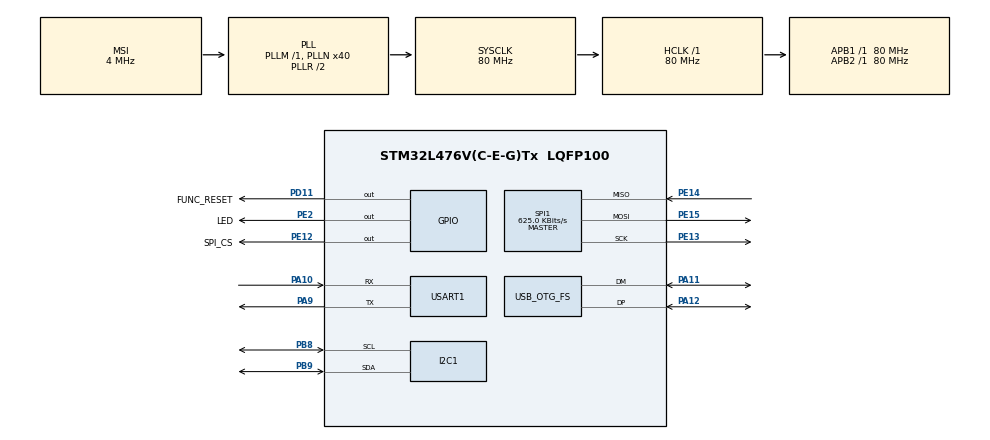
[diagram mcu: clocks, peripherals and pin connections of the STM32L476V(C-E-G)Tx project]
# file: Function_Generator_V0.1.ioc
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I2C1.Timing=0x10D19CE4
Mcu.Family=STM32L4
Mcu.Name=STM32L476V(C-E-G)Tx
Mcu.Package=LQFP100
NVIC.OTG_FS_IRQn=true\:0\:0\:false\:false\:true\:false\:true\:true
NVIC.PriorityGroup=NVIC_PRIORITYGROUP_4
PA10.Mode=Asynchronous
PA10.Signal=USART1_RX
PA11.Mode=Device_Only
PA11.Signal=USB_OTG_FS_DM
PA12.Mode=Device_Only
PA12.Signal=USB_OTG_FS_DP
PA13\ (JTMS-SWDIO).Mode=Serial_Wire
PA13\ (JTMS-SWDIO).Signal=SYS_JTMS-SWDIO
PA14\ (JTCK-SWCLK).Mode=Serial_Wire
PA14\ (JTCK-SWCLK).Signal=SYS_JTCK-SWCLK
PA9.Mode=Asynchronous
PA9.Signal=USART1_TX
PB8.Mode=I2C
PB8.Signal=I2C1_SCL
PB9.Mode=I2C
PB9.Signal=I2C1_SDA
PC14-OSC32_IN\ (PC14).Signal=RCC_OSC32_IN
PC15-OSC32_OUT\ (PC15).Signal=RCC_OSC32_OUT
PD11.GPIO_Label=FUNC_RESET
PD11.Signal=GPIO_Output
PE12.GPIO_Label=SPI_CS
PE12.Signal=GPIO_Output
PE13.Mode=Full_Duplex_Master
PE13.Signal=SPI1_SCK
PE14.Mode=Full_Duplex_Master
PE14.Signal=SPI1_MISO
PE15.Mode=Full_Duplex_Master
PE15.Signal=SPI1_MOSI
PE2.GPIO_Label=LED
PE2.Signal=GPIO_Output
ProjectManager.HeapSize=0x200
ProjectManager.StackSize=0x400
ProjectManager.TargetToolchain=CMake
RCC.ADCFreq_Value=48000000
RCC.AHBFreq_Value=80000000
RCC.APB1Freq_Value=80000000
RCC.APB1TimFreq_Value=80000000
RCC.APB2Freq_Value=80000000
RCC.APB2TimFreq_Value=80000000
RCC.CortexFreq_Value=80000000
RCC.HCLKFreq_Value=80000000
RCC.HSE_VALUE=8000000
RCC.HSI_VALUE=16000000
RCC.MSI_VALUE=4000000
RCC.PLLN=40
RCC.PLLSAI1N=24
RCC.SYSCLKFreq_VALUE=80000000
RCC.SYSCLKSource=RCC_SYSCLKSOURCE_PLLCLK
RCC.USBFreq_Value=48000000
RCC.VCOOutputFreq_Value=160000000
SPI1.BaudRatePrescaler=SPI_BAUDRATEPRESCALER_128
SPI1.CalculateBaudRate=625.0 KBits/s
SPI1.DataSize=SPI_DATASIZE_8BIT
SPI1.Direction=SPI_DIRECTION_2LINES
SPI1.Mode=SPI_MODE_MASTER
SPI1.VirtualType=VM_MASTER
USART1.VirtualMode-Asynchronous=VM_ASYNC
USB_DEVICE.CLASS_NAME_FS=CDC
USB_DEVICE.VirtualMode=Cdc
USB_DEVICE.VirtualModeFS=Cdc_FS
USB_OTG_FS.VirtualMode=Device_Only
VP_USB_DEVICE_VS_USB_DEVICE_CDC_FS.Mode=CDC_FS
board=custom

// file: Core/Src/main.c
/* USER CODE BEGIN Header */
/**
 ******************************************************************************
 * @file           : main.c
 * @brief          : Main program body
 ******************************************************************************
 * @attention
 *
 * Copyright (c) 2025 STMicroelectronics.
 * All rights reserved.
 *
 * This software is licensed under terms that can be found in the LICENSE file
 * in the root directory of this software component.
 * If no LICENSE file comes with this software, it is provided AS-IS.
 *
 ******************************************************************************
 */
/* USER CODE END Header */
#include "main.h"
#include "i2c.h"
#include "spi.h"
#include "usart.h"
#include "usb_device.h"
#include "gpio.h"
#include "usbd_cdc_if.h"
#include "ad9106.h"
#include "cli.h"

void SystemClock_Config(void);

int main(void)
{

  /* MCU Configuration--------------------------------------------------------*/

  /* Reset of all peripherals, Initializes the Flash interface and the Systick. */
  HAL_Init();

  /* Configure the system clock */
  SystemClock_Config();

  /* Initialize all configured peripherals */
  MX_GPIO_Init();
  MX_SPI1_Init();
  MX_USART1_UART_Init();
  MX_USB_DEVICE_Init();
  MX_I2C1_Init();
  /* USER CODE BEGIN 2 */

  HAL_Delay(200);

  HAL_GPIO_WritePin(SPI_CS_GPIO_Port, SPI_CS_Pin, GPIO_PIN_SET);
  HAL_GPIO_WritePin(LED_GPIO_Port, LED_Pin, GPIO_PIN_SET);

  AD9106_Init();
  AD9106_Reset();
  CLI_Init();

  // 2. Configure registers
  /*
    // (a) Power configuration: disable DAC1, DAC2, DAC4 (sleep), keep DAC3 active
    AD9106_WriteReg(0x01, 0b0000000000001101); // DAC1_SLEEP, DAC2_SLEEP, DAC4_SLEEP = 1

    HAL_Delay(10);

    AD9106_ReadReg(0x01);

    HAL_Delay(10);
    // (b) DDS tuning word (sets output frequency)
    AD9106_WriteReg(0x3E, 0x0000); // DDS_TW32 (MSB)

    HAL_Delay(10);
    AD9106_WriteReg(0x3F, 0xFF00); // DDS_TW1  (LSB) → Tuning word = 0x00A300

    HAL_Delay(10);

    AD9106_ReadReg(0x3F);
    HAL_Delay(10);
    // (c) Select waveform source for DAC3 = DDS
    AD9106_WriteReg(0x26, 0x0300); // PRESTORE_SEL3 = 3 (DDS), WAVE_SEL3 = 0 (prestored waveform)
    HAL_Delay(10);
    // (d) Set unity digital gain for DAC3
    AD9106_WriteReg(0x33, 0x0400); // DAC3_DGAIN = +1.0
    HAL_Delay(10);
    // (f) Enable pattern generator
    AD9106_WriteReg(0x1E, 0x0001); // RUN = 1
    HAL_Delay(10);
    AD9106_ReadReg(0x1E);
    HAL_Delay(10);
    // (e) Update all configuration shadow registers
    AD9106_WriteReg(0x1D, 0x0001); // RAMUPDATE = 1
    HAL_Delay(10);

  uint16_t AD910x_SPI_Register_Addresses[66] = {0x0000, 0x0001, 0x0002, 0x0003, 0x0004, 0x0005, 0x0006, 0x0007, 0x0008, 0x0009, 0x000a, 0x000b, 0x000c, 0x000d, 0x000e, 0x001f, 0x0020, 0x0022, 0x0023, 0x0024, 0x0025, 0x0026, 0x0027, 0x0028, 0x0029, 0x002a, 0x002b, 0x002c, 0x002d, 0x002e, 0x002f, 0x0030, 0x0031, 0x0032, 0x0033, 0x0034, 0x0035, 0x0036, 0x0037, 0x003e, 0x003f, 0x0040, 0x0041, 0x0042, 0x0043, 0x0044, 0x0045, 0x0047, 0x0050, 0x0051, 0x0052, 0x0053, 0x0054, 0x0055, 0x0056, 0x0057, 0x0058, 0x0059, 0x005a, 0x005b, 0x005c, 0x005d, 0x005e, 0x005f, 0x001e, 0x001d};
  uint16_t AD9106_example3_regval[66] = {0x0000, 0x0e00, 0x0000, 0x0000, 0x4000, 0x4000, 0x4000, 0x4000, 0x0000, 0x1f00, 0x1f00, 0x1f00, 0x1f00, 0x0000, 0x0000, 0x0000, 0x000e, 0x0000, 0x0000, 0x0000, 0x0000, 0x3232, 0x3232, 0x0111, 0xffff, 0x0101, 0x0101, 0x0003, 0x0000, 0x0000, 0x0000, 0x0000, 0x0000, 0x4000, 0x2000, 0x2000, 0x4000, 0x0001, 0x0200, 0x0a3d, 0x7100, 0x0000, 0x0000, 0x0000, 0x0000, 0x0000, 0x0000, 0x0000, 0x07d0, 0x0000, 0x0000, 0x0100, 0x03e8, 0x0000, 0x0000, 0x0100, 0x0bb8, 0x0000, 0x0000, 0x0100, 0x0fa0, 0x0000, 0x0000, 0x0100, 0x0001, 0x0001};
  uint16_t AD9106_example4_regval[66] = {0x0000, 0x0e00, 0x0000, 0x0000, 0x4000, 0x4000, 0x4000, 0x4000, 0x0000, 0x1f00, 0x1f00, 0x1f00, 0x1f00, 0x0000, 0x0000, 0x0000, 0x000e, 0x0000, 0x0000, 0x0000, 0x0000, 0x1212, 0x1232, 0x0121, 0xffff, 0x0101, 0x0101, 0x0003, 0x0000, 0x0000, 0x0000, 0x0000, 0x0000, 0x4000, 0x4000, 0x4000, 0x4000, 0x1011, 0x0600, 0x1999, 0x9a00, 0x0000, 0x0000, 0x0000, 0x0000, 0x0000, 0x0000, 0x0000, 0x07d0, 0x0000, 0x0000, 0x0001, 0x03e8, 0x0000, 0x0000, 0x0001, 0x03e8, 0x0000, 0x0000, 0x0001, 0x0fa0, 0x0000, 0x0000, 0x16ff, 0x0001, 0x0001};
  uint16_t AD9106_example6_regval[66] = {0x0000, 0x0e00, 0x0000, 0x0000, 0x4000, 0x4000, 0x4000, 0x4000, 0x0000, 0x1f00, 0x1f00, 0x1f00, 0x1f00, 0x0000, 0x0000, 0x0000, 0x000e, 0x0000, 0x0000, 0x0000, 0x0000, 0x1212, 0x1232, 0x0111, 0xffff, 0x0101, 0x0101, 0x0003, 0x0000, 0x0000, 0x0000, 0x0000, 0x0000, 0x4000, 0x4000, 0x4000, 0x4000, 0x0001, 0x7e00, 0x0750, 0x7500, 0x0000, 0x0000, 0x0000, 0x0000, 0x0002, 0x0000, 0x0000, 0x2710, 0x0000, 0x0000, 0x0001, 0x0000, 0x0000, 0x0000, 0x0001, 0x1770, 0x0000, 0x0000, 0x0001, 0x0fa0, 0x0000, 0x0000, 0x7fff, 0x0001, 0x0001};

  for (int i = 0; i < 66; i++)
  {
    AD9106_WriteReg(AD910x_SPI_Register_Addresses[i], AD9106_example4_regval[i]);
    AD9106_ReadReg(AD910x_SPI_Register_Addresses[i]);

    HAL_Delay(10);
  }

   */

  /* USER CODE END 2 */

  /* Infinite loop */
  /* USER CODE BEGIN WHILE */
  while (1)
  {

    CLI_Process();
    HAL_Delay(1);
    /* USER CODE END WHILE */

  }
}

void SystemClock_Config(void)
{
  RCC_OscInitTypeDef RCC_OscInitStruct = {0};
  RCC_ClkInitTypeDef RCC_ClkInitStruct = {0};

  /** Configure the main internal regulator output voltage
   */
  if (HAL_PWREx_ControlVoltageScaling(PWR_REGULATOR_VOLTAGE_SCALE1) != HAL_OK)
  {
    Error_Handler();
  }

  /** Initializes the RCC Oscillators according to the specified parameters
   * in the RCC_OscInitTypeDef structure.
   */
  RCC_OscInitStruct.OscillatorType = RCC_OSCILLATORTYPE_MSI;
  RCC_OscInitStruct.MSIState = RCC_MSI_ON;
  RCC_OscInitStruct.MSICalibrationValue = 0;
  RCC_OscInitStruct.MSIClockRange = RCC_MSIRANGE_6;
  RCC_OscInitStruct.PLL.PLLState = RCC_PLL_ON;
  RCC_OscInitStruct.PLL.PLLSource = RCC_PLLSOURCE_MSI;
  RCC_OscInitStruct.PLL.PLLM = 1;
  RCC_OscInitStruct.PLL.PLLN = 40;
  RCC_OscInitStruct.PLL.PLLP = RCC_PLLP_DIV7;
  RCC_OscInitStruct.PLL.PLLQ = RCC_PLLQ_DIV2;
  RCC_OscInitStruct.PLL.PLLR = RCC_PLLR_DIV2;
  if (HAL_RCC_OscConfig(&RCC_OscInitStruct) != HAL_OK)
  {
    Error_Handler();
  }

  /** Initializes the CPU, AHB and APB buses clocks
   */
  RCC_ClkInitStruct.ClockType = RCC_CLOCKTYPE_HCLK | RCC_CLOCKTYPE_SYSCLK | RCC_CLOCKTYPE_PCLK1 | RCC_CLOCKTYPE_PCLK2;
  RCC_ClkInitStruct.SYSCLKSource = RCC_SYSCLKSOURCE_PLLCLK;
  RCC_ClkInitStruct.AHBCLKDivider = RCC_SYSCLK_DIV1;
  RCC_ClkInitStruct.APB1CLKDivider = RCC_HCLK_DIV1;
  RCC_ClkInitStruct.APB2CLKDivider = RCC_HCLK_DIV1;

  if (HAL_RCC_ClockConfig(&RCC_ClkInitStruct, FLASH_LATENCY_4) != HAL_OK)
  {
    Error_Handler();
  }
}

void Error_Handler(void)
{
  /* USER CODE BEGIN Error_Handler_Debug */
  /* User can add his own implementation to report the HAL error return state */
  __disable_irq();
  while (1)
  {
    NVIC_SystemReset();
  }
  /* USER CODE END Error_Handler_Debug */
}
